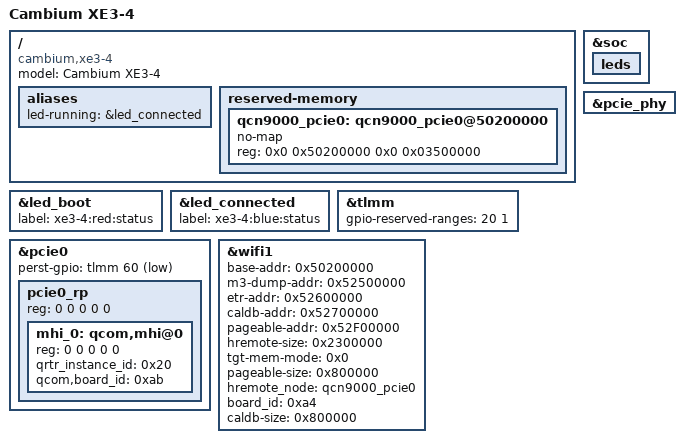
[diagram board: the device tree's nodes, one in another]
// SPDX-License-Identifier: (GPL-2.0+ OR BSD-3-Clause)
/*
 * Cambium XE3-4 device tree source
 *
 * Tri-band Wi-Fi 6E on the AP-CP01-C3 reference design: the XV2-2T's
 * IPQ6018, whose integrated radio serves 2.4 and 5 GHz, plus a QCN9074 on
 * PCIe for the 4x4 6 GHz radio. The vendor's own device tree for it
 * ("Qualcomm Technologies, Inc. IPQ6018/AP-CP01-C3") is the XV2-2T1's with
 * the PCIe root port, its PHY and the qcn9000 node turned on, a reserved
 * region for that radio's host memory, and board SKU 32: flash, ethernet,
 * buttons and the status LED pins are the 2T1's byte for byte, and so is
 * the NOR map.
 *
 * The PCIe radio is left off here. The first image with it on booted silent
 * on a unit with no console, and the 2T1's tree, which this is under the
 * XE3-4's name, has booted and been onboarded on this design; the board is
 * to be brought up on its integrated radio and the 6 GHz radio turned on
 * afterwards, from a reachable system. The tree with the radio on, the
 * root port, its PHY, the qcn9000 node with the OEM's memory map, the 53 MiB
 * qcn9000_pcie0 region and the fourth LED on GPIO 73, is in this file's
 * history. Everything shared with the 2T1 comes from
 * qcom-ipq6018-cambium-xv2-2t.dtsi and qcom-ipq6018-cambium-nor-23.dtsi,
 * the ethernet aliases included: dp1 is ethernet1, so U-Boot's fixup lands
 * eth1addr on eth0 and the label MAC is eth0 - 1.
 *
 * Copyright (c) 2019-2021 The Linux Foundation. All rights reserved.
 */

/dts-v1/;

#include "qcom-ipq6018-cambium-xv2-2t.dtsi"
#include "qcom-ipq6018-cambium-nor-23.dtsi"

/ {
	model = "Cambium XE3-4";
	compatible = "cambium,xe3-4", "qcom,ipq6018-ap-cp01", "qcom,ipq6018";
};

/*
 * The front LED is one BI-COLOUR lamp, not three separate indicators. GPIO 37
 * is its red channel and GPIO 35 its blue one, confirmed on hardware by
 * driving each alone; both together give purple. GPIO 56 - LED2 in the OEM's
 * led-gpio = <73 56 37 35> - drives nothing on this board. The OEM agrees: its
 * LED pin group covers only gpio35, gpio37 and gpio50, and its
 * initial-leds = <0 0 1 0> lights GPIO 37 alone at boot.
 *
 * This is why the board appeared to have dead LEDs. The shared XV2-2T dtsi
 * aliases led-running to GPIO 56, where that board really does have an LED;
 * inherited here it lit red while booting and then handed over to a channel
 * that does not exist, so the unit went dark the moment it finished booting
 * and stayed dark. It reads as a hardware fault and is a wrong alias.
 *
 * Red while booting, in failsafe or upgrading; blue once up. Only ever one
 * channel driven at a time, or the two mix to purple.
 */
/ {
	aliases {
		led-running = &led_connected;
	};
};

&led_boot {
	label = "xe3-4:red:status";
};

&led_connected {
	label = "xe3-4:blue:status";
};

/*
 * GPIO 56 is not wired on this board; keeping it would present a
 * /sys/class/leds entry that silently does nothing, which is what sent the
 * first LED investigation after a phantom hardware fault.
 */
&soc {
	leds {
		/delete-node/ led2;
	};
};

/*
 * GPIO 20 is TrustZone-owned on this board, and reading it from Linux faults.
 * gpiolib calls get_direction() on every line it is not told to leave alone
 * when the pinctrl driver probes, so without this the kernel takes a
 * synchronous external abort in msm_gpio_get_direction() about 0.2 s in,
 * panics, and reboots five seconds later - which from a bootloader log looks
 * exactly like the AArch64 handoff failing, because nothing has reached the
 * console yet. The same access reset this unit twice during recon, through
 * `cat /sys/kernel/debug/gpio` on the stock firmware.
 *
 * Stock boots without this because its 4.4 kernel's gpiolib does not sweep
 * get_direction() over every line. The XV2-2T0 and 2T1 boot without it too,
 * so the protection is specific to this model and the reservation is kept
 * here rather than in the shared dtsi. GPIO 20 is used by nothing in either
 * tree. The in-tree ipq60xx boards that do touch it - wallys-dr6018,
 * wallys-dr6018-v4 and emplus-wap386v2 - all reserve exactly this range.
 */
&tlmm {
	gpio-reserved-ranges = <20 1>;
};

/*
 * The 6 GHz radio. The 2T dtsi keeps the PCIe root port, its PHY and the
 * qcn9000 node off because those boards have no add-in radio; this one has a
 * QCN9074 (17cb:1104) at 0000:01:00.0 behind the root port, held in reset
 * through GPIO 60 as on the reference design. The properties on wifi1 are the
 * OEM node's values; they belong to the vendor's cnss2 binding, and ath11k
 * reads only qrtr_instance_id, memory-region and qcom,board_id from the root
 * port's mhi node.
 *
 * The host-memory region is the OEM's 45 MiB plus the 8 MiB pageable window
 * at 0x52F00000 that pageable-addr/pageable-size name, hence 0x3500000 rather
 * than the OEM DTB's 0x2d00000. It is clear of everything this target
 * reserves: our wcnss region is 0x3700000 and the whole reserved map ends
 * below 0x4E500000, and unlike the stock tree we declare no dma_pool0 at
 * 0x52F00000. Checked against the compiled radio-off DTB, not assumed.
 *
 * The OEM tree also lists a fourth status LED on GPIO 73. It is left out
 * here: it is cosmetic, GPIO 73 has never been driven from Linux on this
 * board, and this image exists to test the radio. The ethernet aliases stay
 * as the 2T dtsi sets them - dp1 as ethernet1, label MAC = eth0 - 1 - which
 * is the arrangement this unit has now onboarded through.
 */
/ {
	reserved-memory {
		qcn9000_pcie0: qcn9000_pcie0@50200000 {
			no-map;
			reg = <0x0 0x50200000 0x0 0x03500000>;
		};
	};
};

&pcie_phy {
	status = "ok";
};

&pcie0 {
	perst-gpio = <&tlmm 60 GPIO_ACTIVE_LOW>;
	status = "ok";

	pcie0_rp {
		reg = <0 0 0 0 0>;

		mhi_0: qcom,mhi@0 {
			reg = <0 0 0 0 0>;
			qrtr_instance_id = <0x20>;
			/*
			 * The id the stock firmware really loads the board file
			 * under: cnss2.bdf_pci0=0xab on its command line, over
			 * the OEM node's 0xa4, and the file's own header says
			 * 0xab. Only consulted for a board-2.bin bundle; the
			 * image ships a flat board.bin.
			 */
			qcom,board_id = <0xab>;
		};
	};
};

&wifi1 {
	base-addr = <0x50200000>;
	m3-dump-addr = <0x52500000>;
	etr-addr = <0x52600000>;
	caldb-addr = <0x52700000>;
	pageable-addr = <0x52F00000>;
	hremote-size = <0x2300000>;
	tgt-mem-mode = <0x0>;
	pageable-size = <0x800000>;
	hremote_node = <&qcn9000_pcie0>;
	board_id = <0xa4>;
	caldb-size = <0x800000>;
	status = "ok";
};
